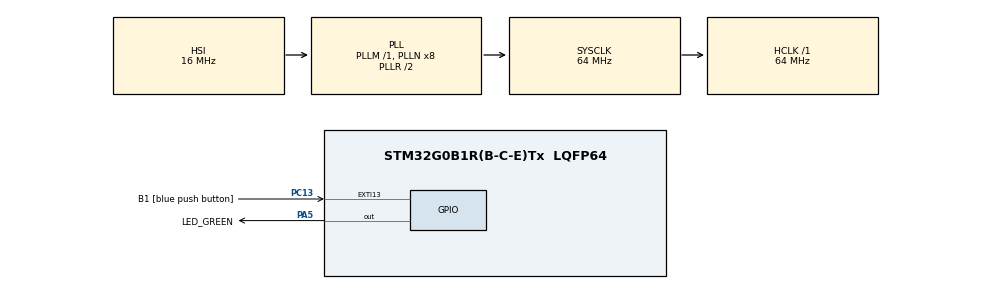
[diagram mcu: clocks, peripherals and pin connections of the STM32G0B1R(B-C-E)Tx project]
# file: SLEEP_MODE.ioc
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Mcu.Family=STM32G0
Mcu.Name=STM32G0B1R(B-C-E)Tx
Mcu.Package=LQFP64
PA13.GPIO_Label=TMS
PA13.Signal=SYS_SWDIO
PA14-BOOT0.GPIO_Label=TCK
PA14-BOOT0.Signal=SYS_SWCLK
PA2.GPIO_Label=USART2_TX [STLK_TX]
PA2.Signal=USART2_TX
PA3.GPIO_Label=USART2_RX [STLK_RX]
PA3.Signal=USART2_RX
PA5.GPIO_Label=LED_GREEN
PA5.GPIO_Speed=GPIO_SPEED_FREQ_HIGH
PA5.Signal=GPIO_Output
PC13.GPIO_Label=B1 [blue push button]
PC13.Signal=GPXTI13
PC14-OSC32_IN\ (PC14).Signal=RCC_OSC32_IN
PC15-OSC32_OUT\ (PC15).Signal=RCC_OSC32_OUT
PF0-OSC_IN\ (PF0).GPIO_Label=MCO
PF0-OSC_IN\ (PF0).Signal=RCC_OSC_IN
ProjectManager.HeapSize=0x200
ProjectManager.StackSize=0x400
ProjectManager.TargetToolchain=STM32CubeIDE
RCC.ADCFreq_Value=64000000
RCC.AHBFreq_Value=64000000
RCC.CortexFreq_Value=64000000
RCC.EXTERNAL_CLOCK_VALUE=12288000
RCC.HCLKFreq_Value=64000000
RCC.HSE_VALUE=8000000
RCC.HSI48_VALUE=48000000
RCC.HSI_VALUE=16000000
RCC.LSE_VALUE=32768
RCC.SYSCLKFreq_VALUE=64000000
RCC.SYSCLKSource=RCC_SYSCLKSOURCE_PLLCLK
RCC.USBFreq_Value=48000000
RCC.VCOOutputFreq_Value=128000000
board=NUCLEO-G0B1RE

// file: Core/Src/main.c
/* USER CODE BEGIN Header */
/**
  ******************************************************************************
  * @file           : main.c
  * @brief          : Main program body
  ******************************************************************************
  * @attention
  *
  * Copyright (c) 2025 STMicroelectronics.
  * All rights reserved.
  *
  * This software is licensed under terms that can be found in the LICENSE file
  * in the root directory of this software component.
  * If no LICENSE file comes with this software, it is provided AS-IS.
  *
  ******************************************************************************
  */
/* USER CODE END Header */
#include "main.h"

void SystemClock_Config(void);
static void MX_GPIO_Init(void);

int main(void)
{

  /* MCU Configuration--------------------------------------------------------*/

  /* Reset of all peripherals, Initializes the Flash interface and the Systick. */
  HAL_Init();

  /* Configure the system clock */
  SystemClock_Config();

  /* Initialize all configured peripherals */
  MX_GPIO_Init();

  /* Infinite loop */
  while (1)
  {

    /* USER CODE BEGIN 3 */

	    HAL_Delay(1000);
	    HAL_SuspendTick();
	    HAL_PWR_EnterSLEEPMode(PWR_MAINREGULATOR_ON,PWR_SLEEPENTRY_WFI);
	    HAL_ResumeTick();

  }
  /* USER CODE END 3 */
}

void SystemClock_Config(void)
{
  RCC_OscInitTypeDef RCC_OscInitStruct = {0};
  RCC_ClkInitTypeDef RCC_ClkInitStruct = {0};

  /** Configure the main internal regulator output voltage
  */
  HAL_PWREx_ControlVoltageScaling(PWR_REGULATOR_VOLTAGE_SCALE1);

  /** Initializes the RCC Oscillators according to the specified parameters
  * in the RCC_OscInitTypeDef structure.
  */
  RCC_OscInitStruct.OscillatorType = RCC_OSCILLATORTYPE_HSI;
  RCC_OscInitStruct.HSIState = RCC_HSI_ON;
  RCC_OscInitStruct.HSIDiv = RCC_HSI_DIV1;
  RCC_OscInitStruct.HSICalibrationValue = RCC_HSICALIBRATION_DEFAULT;
  RCC_OscInitStruct.PLL.PLLState = RCC_PLL_ON;
  RCC_OscInitStruct.PLL.PLLSource = RCC_PLLSOURCE_HSI;
  RCC_OscInitStruct.PLL.PLLM = RCC_PLLM_DIV1;
  RCC_OscInitStruct.PLL.PLLN = 8;
  RCC_OscInitStruct.PLL.PLLP = RCC_PLLP_DIV2;
  RCC_OscInitStruct.PLL.PLLQ = RCC_PLLQ_DIV2;
  RCC_OscInitStruct.PLL.PLLR = RCC_PLLR_DIV2;
  if (HAL_RCC_OscConfig(&RCC_OscInitStruct) != HAL_OK)
  {
    Error_Handler();
  }

  /** Initializes the CPU, AHB and APB buses clocks
  */
  RCC_ClkInitStruct.ClockType = RCC_CLOCKTYPE_HCLK|RCC_CLOCKTYPE_SYSCLK
                              |RCC_CLOCKTYPE_PCLK1;
  RCC_ClkInitStruct.SYSCLKSource = RCC_SYSCLKSOURCE_PLLCLK;
  RCC_ClkInitStruct.AHBCLKDivider = RCC_SYSCLK_DIV1;
  RCC_ClkInitStruct.APB1CLKDivider = RCC_HCLK_DIV1;

  if (HAL_RCC_ClockConfig(&RCC_ClkInitStruct, FLASH_LATENCY_2) != HAL_OK)
  {
    Error_Handler();
  }
}

static void MX_GPIO_Init(void)
{
  GPIO_InitTypeDef GPIO_InitStruct = {0};

  /* GPIO Ports Clock Enable */
  __HAL_RCC_GPIOC_CLK_ENABLE();
  __HAL_RCC_GPIOF_CLK_ENABLE();
  __HAL_RCC_GPIOA_CLK_ENABLE();
  __HAL_RCC_GPIOB_CLK_ENABLE();
  __HAL_RCC_GPIOD_CLK_ENABLE();

  /*Configure GPIO pin Output Level */
  HAL_GPIO_WritePin(LED_GREEN_GPIO_Port, LED_GREEN_Pin, GPIO_PIN_RESET);

  /*Configure GPIO pins : PC11 PC12 PC0 PC1
                           PC2 PC3 PC4 PC5
                           PC6 PC7 PC8 PC9
                           PC10 */
  GPIO_InitStruct.Pin = GPIO_PIN_11|GPIO_PIN_12|GPIO_PIN_0|GPIO_PIN_1
                          |GPIO_PIN_2|GPIO_PIN_3|GPIO_PIN_4|GPIO_PIN_5
                          |GPIO_PIN_6|GPIO_PIN_7|GPIO_PIN_8|GPIO_PIN_9
                          |GPIO_PIN_10;
  GPIO_InitStruct.Mode = GPIO_MODE_ANALOG;
  GPIO_InitStruct.Pull = GPIO_NOPULL;
  HAL_GPIO_Init(GPIOC, &GPIO_InitStruct);

  /*Configure GPIO pin : B1_Pin */
  GPIO_InitStruct.Pin = B1_Pin;
  GPIO_InitStruct.Mode = GPIO_MODE_IT_RISING;
  GPIO_InitStruct.Pull = GPIO_NOPULL;
  HAL_GPIO_Init(B1_GPIO_Port, &GPIO_InitStruct);

  /*Configure GPIO pins : PF1 PF2 */
  GPIO_InitStruct.Pin = GPIO_PIN_1|GPIO_PIN_2;
  GPIO_InitStruct.Mode = GPIO_MODE_ANALOG;
  GPIO_InitStruct.Pull = GPIO_NOPULL;
  HAL_GPIO_Init(GPIOF, &GPIO_InitStruct);

  /*Configure GPIO pins : PA0 PA1 PA4 PA6
                           PA7 PA8 PA9 PA10
                           PA11 PA12 PA15 */
  GPIO_InitStruct.Pin = GPIO_PIN_0|GPIO_PIN_1|GPIO_PIN_4|GPIO_PIN_6
                          |GPIO_PIN_7|GPIO_PIN_8|GPIO_PIN_9|GPIO_PIN_10
                          |GPIO_PIN_11|GPIO_PIN_12|GPIO_PIN_15;
  GPIO_InitStruct.Mode = GPIO_MODE_ANALOG;
  GPIO_InitStruct.Pull = GPIO_NOPULL;
  HAL_GPIO_Init(GPIOA, &GPIO_InitStruct);

  /*Configure GPIO pins : USART2_TX_Pin USART2_RX_Pin */
  GPIO_InitStruct.Pin = USART2_TX_Pin|USART2_RX_Pin;
  GPIO_InitStruct.Mode = GPIO_MODE_AF_PP;
  GPIO_InitStruct.Pull = GPIO_NOPULL;
  GPIO_InitStruct.Speed = GPIO_SPEED_FREQ_LOW;
  GPIO_InitStruct.Alternate = GPIO_AF1_USART2;
  HAL_GPIO_Init(GPIOA, &GPIO_InitStruct);

  /*Configure GPIO pin : LED_GREEN_Pin */
  GPIO_InitStruct.Pin = LED_GREEN_Pin;
  GPIO_InitStruct.Mode = GPIO_MODE_OUTPUT_PP;
  GPIO_InitStruct.Pull = GPIO_NOPULL;
  GPIO_InitStruct.Speed = GPIO_SPEED_FREQ_HIGH;
  HAL_GPIO_Init(LED_GREEN_GPIO_Port, &GPIO_InitStruct);

  /*Configure GPIO pins : PB0 PB1 PB2 PB10
                           PB11 PB12 PB13 PB14
                           PB15 PB3 PB4 PB5
                           PB6 PB7 PB8 PB9 */
  GPIO_InitStruct.Pin = GPIO_PIN_0|GPIO_PIN_1|GPIO_PIN_2|GPIO_PIN_10
                          |GPIO_PIN_11|GPIO_PIN_12|GPIO_PIN_13|GPIO_PIN_14
                          |GPIO_PIN_15|GPIO_PIN_3|GPIO_PIN_4|GPIO_PIN_5
                          |GPIO_PIN_6|GPIO_PIN_7|GPIO_PIN_8|GPIO_PIN_9;
  GPIO_InitStruct.Mode = GPIO_MODE_ANALOG;
  GPIO_InitStruct.Pull = GPIO_NOPULL;
  HAL_GPIO_Init(GPIOB, &GPIO_InitStruct);

  /*Configure GPIO pins : PD8 PD9 PD0 PD1
                           PD2 PD3 PD4 PD5
                           PD6 */
  GPIO_InitStruct.Pin = GPIO_PIN_8|GPIO_PIN_9|GPIO_PIN_0|GPIO_PIN_1
                          |GPIO_PIN_2|GPIO_PIN_3|GPIO_PIN_4|GPIO_PIN_5
                          |GPIO_PIN_6;
  GPIO_InitStruct.Mode = GPIO_MODE_ANALOG;
  GPIO_InitStruct.Pull = GPIO_NOPULL;
  HAL_GPIO_Init(GPIOD, &GPIO_InitStruct);

}

void Error_Handler(void)
{
  __disable_irq();
  while (1)
  {
  }
}
